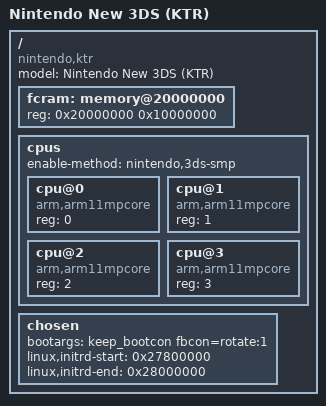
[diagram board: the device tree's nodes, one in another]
// SPDX-License-Identifier: GPL-2.0
/*
 * Support for:
 *   - New Nintendo 3DS    (KTR-001)
 *   - New Nintendo 3DS XL (RED-001)
 *   - New Nintendo 2DS XL (JAN-001)
 */
/dts-v1/;

#include "nintendo3ds.dtsi"

/ {
	model = "Nintendo New 3DS (KTR)";
	compatible = "nintendo,ktr", "nintendo,3ds";

	fcram: memory@20000000 {
		device_type = "memory";
		reg = <0x20000000 0x10000000>;
	};

	cpus {
		#address-cells = <1>;
		#size-cells = <0>;
		enable-method = "nintendo,3ds-smp";

		cpu@0 {
			device_type = "cpu";
			compatible = "arm,arm11mpcore";
			reg = <0>;
		};

		cpu@1 {
			device_type = "cpu";
			compatible = "arm,arm11mpcore";
			reg = <1>;
		};

		cpu@2 {
			device_type = "cpu";
			compatible = "arm,arm11mpcore";
			reg = <2>;
		};

		cpu@3 {
			device_type = "cpu";
			compatible = "arm,arm11mpcore";
			reg = <3>;
		};
	};

	chosen {
		bootargs = "keep_bootcon fbcon=rotate:1";
		// At the end of the CTR fcram
		linux,initrd-start = <0x27800000>;
		linux,initrd-end = <0x28000000>; // 8 MiB
	};
};
